# M481_v1 register map
File version: 1.0
Registers are 32-bit, read-write, reset 0x0 unless marked. A register's access mark holds for its fields unless they carry their own. Offsets are from the block's base; [hi:lo] are bit positions; {n}, {i} and the like mark numbered series; 'fields as' and 'values as' point back to an identical list.

## EADC0 — EADC Register Map
Base 0x40043000
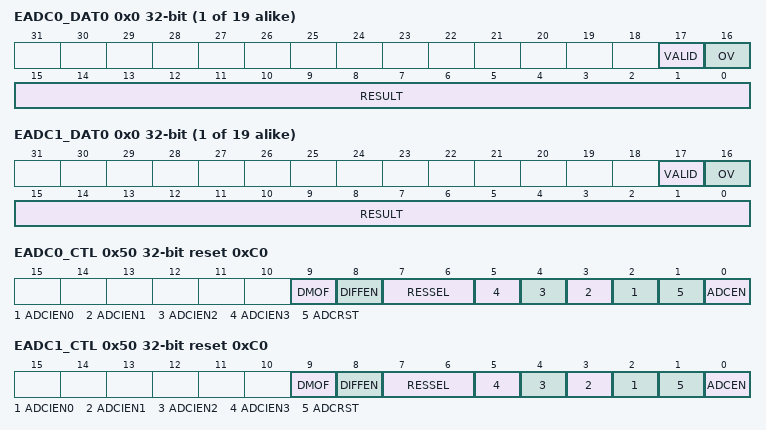
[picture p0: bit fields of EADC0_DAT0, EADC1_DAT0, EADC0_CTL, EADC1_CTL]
{0x0+4i} EADC0_DAT{i} ro (i=0..18) — EADC Data Register {i} for Sample Module {i}
  [17] VALID — Valid Flag. This bit is set to 1 when corresponding sample module channel analog input conversion is completed and cleared by hardware after EADC_DAT register is read.
    0=Data in RESULT[11:0] bits is not valid; 1=Data in RESULT[11:0] bits is valid
  [16] OV — Overrun Flag. If converted data in RESULT[11:0] has not been read before new conversion result is loaded to this register, OV is set to 1. Note: It is cleared by hardware after EADC_DAT register is read.
    0=Data in RESULT[11:0] is recent conversion result; 1=Data in RESULT[11:0] is overwrite
  [15:0] RESULT — EADC Conversion Result. This field contains 12 bits conversion result. When DMOF (EADC_CTL[9]) is set to 0, 12-bit EADC conversion result with unsigned format will be filled in RESULT[11:0] and zero will be filled in RESULT[15:12]. When DMOF (EADC_CTL[9]) set to 1, 12-bit EADC conversion result with 2'complement format will be filled in RESULT[11:0] and signed bits to will be filled in RESULT[15:12].
{0x0+4i} EADC1_DAT{i} ro (alternate view of EADC0_DAT{i}) (i=0..18) — EADC Data Register {i} for Sample Module {i}
  fields as EADC0_DAT0
0x4C EADC0_CURDAT ro — EADC PDMA Current Transfer Data Register
  [17:0] CURDAT — EADC PDMA Current Transfer Data (Read Only)
0x4C EADC1_CURDAT ro (alternate view of EADC0_CURDAT) — EADC PDMA Current Transfer Data Register
  [17:0] CURDAT — EADC PDMA Current Transfer Data (Read Only)
0x50 EADC0_CTL reset 0xC0 — EADC Control Register
  [9] DMOF — EADC Differential Input Mode Output Format
    0=EADC conversion result will be filled in RESULT (EADC_DATn[15:0], where n= 0 ~18) with unsigned format; 1=EADC conversion result will be filled in RESULT (EADC_DATn[15:0], where n= 0 ~18) with 2'complement format
  [8] DIFFEN — Differential Analog Input Mode Enable Bit
    0=Single-end analog input mode; 1=Differential analog input mode
  [7:6] RESSEL — Resolution Selection
    0=6-bit EADC result will be put at RESULT (EADC_DATn[5:0]); 1=8-bit EADC result will be put at RESULT (EADC_DATn[7:0]); 2=10-bit EADC result will be put at RESULT (EADC_DATn[9:0]); 3=12-bit EADC result will be put at RESULT (EADC_DATn[11:0])
  [n+2] ADCIEN{n} (n=0..3) — Specific Sample Module EADC ADINT{n} Interrupt Enable Bit. The EADC converter generates a conversion end ADIF{n} (EADC_STATUS2[{n}]) upon the end of specific sample module EADC conversion. If EADCIEN{n} bit is set then conversion end interrupt request ADINT{n} is generated.
    0=Specific sample module EADC ADINT{n} interrupt function Disabled; 1=Specific sample module EADC ADINT{n} interrupt function Enabled
  [1] ADCRST — EADC Converter Control Circuits Reset. Note: EADCRST bit remains 1 during EADC reset, when EADC reset end, the EADCRST bit is automatically cleared to 0.
    0=No effect; 1=Cause EADC control circuits reset to initial state, but not change the EADC registers value
  [0] ADCEN — EADC Converter Enable Bit. Note: Before starting EADC conversion function, this bit should be set to 1. Clear it to 0 to disable EADC converter analog circuit power consumption.
    0=Disabled EADC; 1=Enabled EADC
0x50 EADC1_CTL reset 0xC0 (alternate view of EADC0_CTL) — EADC Control Register
  fields as EADC0_CTL
0x54 EADC0_SWTRG wo — EADC Sample Module Software Start Register
  [18:0] SWTRG — EADC Sample Module 0~18 Software Force to Start EADC Conversion. Note: After writing this register to start EADC conversion, the EADC_PENDSTS register will show which sample module will conversion. If user want to disable the conversion of the sample module, user can write EADC_PENDSTS register to clear it.
    0=No effect; 1=Cause an EADC conversion when the priority is given to sample module
0x54 EADC1_SWTRG wo (alternate view of EADC0_SWTRG) — EADC Sample Module Software Start Register
  fields as EADC0_SWTRG
0x58 EADC0_PENDSTS — EADC Start of Conversion Pending Flag Register
  [18:0] STPF — EADC Sample Module 0~18 Start of Conversion Pending Flag. Read Operation:
    0=There is no pending conversion for sample module; 1=Sample module EADC start of conversion is pending. Cear pending flag cancel the conversion for sample module
0x58 EADC1_PENDSTS (alternate view of EADC0_PENDSTS) — EADC Start of Conversion Pending Flag Register
  fields as EADC0_PENDSTS
0x5C EADC0_OVSTS — EADC Sample Module Start of Conversion Overrun Flag Register
  [18:0] SPOVF — EADC SAMPLE0~18 Overrun Flag. Note: This bit is cleared by writing 1 to it.
    0=No sample module event overrun; 1=Indicates a new sample module event is generated while an old one event is pending
0x5C EADC1_OVSTS (alternate view of EADC0_OVSTS) — EADC Sample Module Start of Conversion Overrun Flag Register
  fields as EADC0_OVSTS
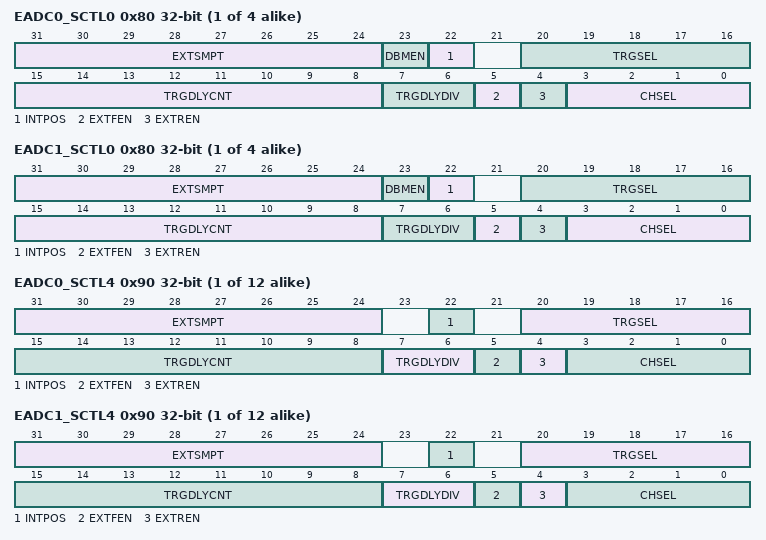
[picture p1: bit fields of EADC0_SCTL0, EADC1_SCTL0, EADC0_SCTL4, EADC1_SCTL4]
{0x80+4i} EADC0_SCTL{i} (i=0..3) — EADC Sample Module {i} Control Register
  [31:24] EXTSMPT — EADC Sampling Time Extend. When EADC converting at high conversion rate, the sampling time of analog input voltage may not enough if input channel loading is heavy, user can extend EADC sampling time after trigger source is coming to get enough sampling time. The range of start delay time is from 0~255 EADC clock.
  [23] DBMEN — Double Buffer Mode Enable Bit
    0=Sample has one sample result register (default); 1=Sample has two sample result registers
  [22] INTPOS — Interrupt Flag Position Select
    0=Set ADIFn (EADC_STATUS2[n], n=0~3) at EADC end of conversion; 1=Set ADIFn (EADC_STATUS2[n], n=0~3) at EADC start of conversion
  [20:16] TRGSEL — EADC Sample Module Start of Conversion Trigger Source Selection
  [15:8] TRGDLYCNT — EADC Sample Module Start of Conversion Trigger Delay Time
  [7:6] TRGDLYDIV — EADC Sample Module Start of Conversion Trigger Delay Clock Divider Selection. Trigger delay clock frequency:
    0=EADC_CLK/1; 1=EADC_CLK/2; 2=EADC_CLK/4; 3=EADC_CLK/16
  [5] EXTFEN — EADC External Trigger Falling Edge Enable Bit
    0=Falling edge Disabled when EADC selects EADC0_ST as trigger source; 1=Falling edge Enabled when EADC selects EADC0_ST as trigger source
  [4] EXTREN — EADC External Trigger Rising Edge Enable Bit
    0=Rising edge Disabled when EADC selects EADC0_ST as trigger source; 1=Rising edge Enabled when EADC selects EADC0_ST as trigger source
  [3:0] CHSEL — EADC Sample Module Channel Selection
{0x80+4i} EADC1_SCTL{i} (alternate view of EADC0_SCTL{i}) (i=0..3) — EADC Sample Module {i} Control Register
  fields as EADC0_SCTL0
{0x80+4i} EADC0_SCTL{i} (i=4..15) — EADC Sample Module {i} Control Register
  [31:24] EXTSMPT — EADC Sampling Time Extend. When EADC converting at high conversion rate, the sampling time of analog input voltage may not enough if input channel loading is heavy, SW can extend EADC sampling time after trigger source is coming to get enough sampling time. The range of start delay time is from 0~255 EADC clock.
  [22] INTPOS — Interrupt Flag Position Select
    values as EADC0_SCTL0.INTPOS
  [20:16] TRGSEL — EADC Sample Module Start of Conversion Trigger Source Selection
  [15:8] TRGDLYCNT — EADC Sample Module Start of Conversion Trigger Delay Time
  [7:6] TRGDLYDIV — EADC Sample Module Start of Conversion Trigger Delay Clock Divider Selection. Trigger delay clock frequency:
    0=EADC_CLK/1; 1=EADC_CLK/2; 2=EADC_CLK/4; 3=EADC_CLK/16
  [5] EXTFEN — EADC External Trigger Falling Edge Enable Bit
    values as EADC0_SCTL0.EXTFEN
  [4] EXTREN — EADC External Trigger Rising Edge Enable Bit
    values as EADC0_SCTL0.EXTREN
  [3:0] CHSEL — EADC Sample Module Channel Selection
{0x80+4i} EADC1_SCTL{i} (alternate view of EADC0_SCTL{i}) (i=4..15) — EADC Sample Module {i} Control Register
  fields as EADC0_SCTL4
{0x80+4i} EADC0_SCTL{i} (i=16..18) — EADC Sample Module {i} Control Register
  [31:24] EXTSMPT — EADC Sampling Time Extend. When EADC converting at high conversion rate, the sampling time of analog input voltage may not enough if input channel loading is heavy, SW can extend EADC sampling time after trigger source is coming to get enough sampling time. The range of start delay time is from 0~255 EADC clock.
{0x80+4i} EADC1_SCTL{i} (alternate view of EADC0_SCTL{i}) (i=16..18) — EADC Sample Module {i} Control Register
  fields as EADC0_SCTL16
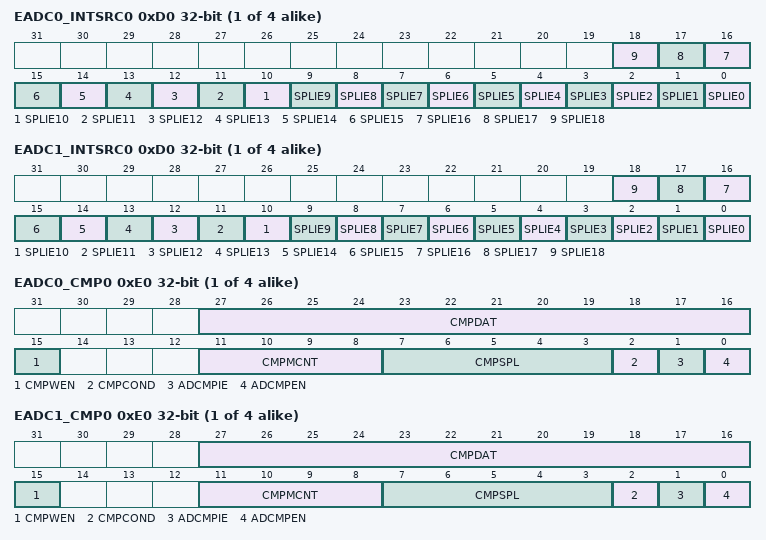
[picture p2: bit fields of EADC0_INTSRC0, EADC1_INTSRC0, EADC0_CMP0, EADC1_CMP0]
{0xD0+4i} EADC0_INTSRC{i} (i=0..3) — EADC Interrupt {i} Source Enable Control Register.
  [n] SPLIE{n} (n=0..18) — Sample Module {n} Interrupt Enable Bit
    0=Sample Module {n} interrupt Disabled; 1=Sample Module {n} interrupt Enabled
{0xD0+4i} EADC1_INTSRC{i} (alternate view of EADC0_INTSRC{i}) (i=0..3) — EADC Interrupt {i} Source Enable Control Register.
  fields as EADC0_INTSRC0
{0xE0+4i} EADC0_CMP{i} (i=0..3) — EADC Result Compare Register {i}
  [27:16] CMPDAT — Comparison Data. The 12 bits data is used to compare with conversion result of specified sample module. User can use it to monitor the external analog input pin voltage transition without imposing a load on software.
  [15] CMPWEN — Compare Window Mode Enable Bit. Note: This bit is only present in EADC_CMP0 and EADC_CMP2 register.
    0=EADCMPF0 (EADC_STATUS2[4]) will be set when EADC_CMP0 compared condition matched. EADCMPF2 (EADC_STATUS2[6]) will be set when EADC_CMP2 compared condition matched; 1=EADCMPF0 (EADC_STATUS2[4]) will be set when both EADC_CMP0 and EADC_CMP1 compared condition matched. EADCMPF2 (EADC_STATUS2[6]) will be set when both EADC_CMP2 and EADC_CMP3 compared condition matched
  [11:8] CMPMCNT — Compare Match Count
  [7:3] CMPSPL — Compare Sample Module Selection
    {v}=Sample Module {v} conversion result EADC_DAT{v} is selected to be compared (v=0..18)
  [2] CMPCOND — Compare Condition
    0=Set the compare condition as that when a 12-bit EADC conversion result is less than the 12-bit CMPDAT (EADC_CMPn [27:16]), the internal match counter will increase one; 1=Set the compare condition as that when a 12-bit EADC conversion result is greater or equal to the 12-bit CMPDAT (EADC_CMPn [27:16]), the internal match counter will increase one
  [1] ADCMPIE — EADC Result Compare Interrupt Enable Bit
    0=Compare function interrupt Disabled; 1=Compare function interrupt Enabled
  [0] ADCMPEN — EADC Result Compare Enable Bit
    0=Compare Disabled; 1=Compare Enabled
{0xE0+4i} EADC1_CMP{i} (alternate view of EADC0_CMP{i}) (i=0..3) — EADC Result Compare Register {i}
  fields as EADC0_CMP0
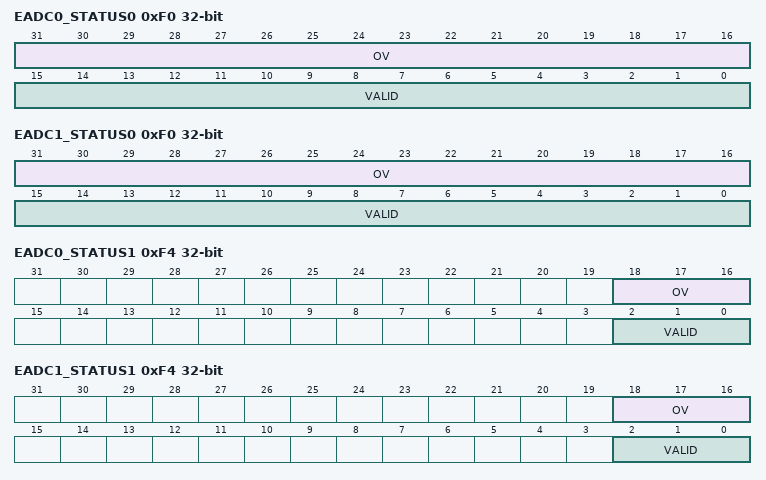
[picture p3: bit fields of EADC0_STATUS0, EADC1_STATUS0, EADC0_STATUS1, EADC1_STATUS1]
0xF0 EADC0_STATUS0 ro — EADC Status Register 0
  [31:16] OV — EADC_DAT0~15 Overrun Flag
  [15:0] VALID — EADC_DAT0~15 Data Valid Flag
0xF0 EADC1_STATUS0 ro (alternate view of EADC0_STATUS0) — EADC Status Register 0
  fields as EADC0_STATUS0
0xF4 EADC0_STATUS1 ro — EADC Status Register 1
  [18:16] OV — EADC_DAT16~18 Overrun Flag
  [2:0] VALID — EADC_DAT16~18 Data Valid Flag
0xF4 EADC1_STATUS1 ro (alternate view of EADC0_STATUS1) — EADC Status Register 1
  fields as EADC0_STATUS1
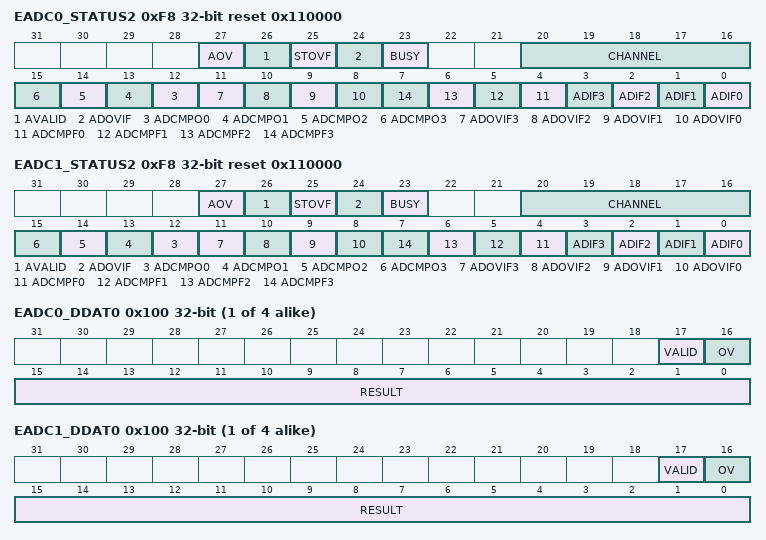
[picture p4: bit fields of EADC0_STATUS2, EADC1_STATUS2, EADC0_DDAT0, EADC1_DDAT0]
0xF8 EADC0_STATUS2 reset 0x110000 — EADC Status Register 2
  [27] AOV ro — for All Sample Module EADC Result Data Register Overrun Flags Check (Read Only). Note: This bit will keep 1 when any OVn Flag is equal to 1.
    0=None of sample module data register overrun flag OVn (EADC_DATn[16]) is set to 1; 1=Any one of sample module data register overrun flag OVn (EADC_DATn[16]) is set to 1
  [26] AVALID ro — for All Sample Module EADC Result Data Register EADC_DAT Data Valid Flag Check (Read Only). Note: This bit will keep 1 when any VALIDn Flag is equal to 1.
    0=None of sample module data register valid flag VALIDn (EADC_DATn[17]) is set to 1; 1=Any one of sample module data register valid flag VALIDn (EADC_DATn[17]) is set to 1
  [25] STOVF ro — for All EADC Sample Module Start of Conversion Overrun Flags Check (Read Only). Note: This bit will keep 1 when any SPOVFn Flag is equal to 1.
    0=None of sample module event overrun flag SPOVFn (EADC_OVSTS[n]) is set to 1; 1=Any one of sample module event overrun flag SPOVFn (EADC_OVSTS[n]) is set to 1
  [24] ADOVIF ro — All EADC Interrupt Flag Overrun Bits Check (Read Only). Note: This bit will keep 1 when any ADOVIFn Flag is equal to 1.
    0=None of ADINT interrupt flag ADOVIFn (EADC_STATUS2[11:8]) is overwritten to 1; 1=Any one of ADINT interrupt flag ADOVIFn (EADC_STATUS2[11:8]) is overwritten to 1
  [23] BUSY ro — Busy/Idle (Read Only)
    0=EADC is in idle state; 1=EADC is busy at conversion
  [20:16] CHANNEL ro — Current Conversion Channel (Read Only)
  [n+12] ADCMPO{n} ro (n=0..3) — EADC Compare {n} Output Status (Read Only). The 12 bits compare{n} data CMPDAT{n} (EADC_CMP{n}[27:16]) is used to compare with conversion result of specified sample module. User can use it to monitor the external analog input pin voltage status.
    0=Conversion result in EADC_DAT less than CMPDAT{n} setting; 1=Conversion result in EADC_DAT great than or equal CMPDAT{n} setting
  [11] ADOVIF3 — EADC ADINT3 Interrupt Flag Overrun. Note: This bit is cleared by writing 1 to it.
    0=ADINT3 interrupt flag is not overwritten to 1; 1=ADINT3 interrupt flag is overwritten to 1
  [10] ADOVIF2 — EADC ADINT2 Interrupt Flag Overrun. Note: This bit is cleared by writing 1 to it.
    0=ADINT2 interrupt flag is not overwritten to 1; 1=ADINT2 interrupt flag is s overwritten to 1
  [9] ADOVIF1 — EADC ADINT1 Interrupt Flag Overrun. Note: This bit is cleared by writing 1 to it.
    0=ADINT1 interrupt flag is not overwritten to 1; 1=ADINT1 interrupt flag is overwritten to 1
  [8] ADOVIF0 — EADC ADINT0 Interrupt Flag Overrun. Note: This bit is cleared by writing 1 to it.
    0=ADINT0 interrupt flag is not overwritten to 1; 1=ADINT0 interrupt flag is overwritten to 1
  [n+4] ADCMPF{n} (n=0..3) — EADC Compare {n} Flag. When the specific sample module EADC conversion result meets setting condition in EADC_CMP{n} then this bit is set to 1. Note: This bit is cleared by writing 1 to it.
    0=Conversion result in EADC_DAT does not meet EADC_CMP{n} register setting; 1=Conversion result in EADC_DAT meets EADC_CMP{n} register setting
  [n] ADIF{n} (n=0..3) — EADC ADINT{n} Interrupt Flag. Note 1: This bit is cleared by writing 1 to it. Note 2:This bit indicates whether an EADC conversion of specific sample module has been completed
    0=No ADINT{n} interrupt pulse received; 1=ADINT{n} interrupt pulse has been received
0xF8 EADC1_STATUS2 reset 0x110000 (alternate view of EADC0_STATUS2) — EADC Status Register 2
  fields as EADC0_STATUS2
0xFC EADC0_STATUS3 ro reset 0x1F — EADC Status Register 3
  [4:0] CURSPL — EADC Current Sample Module (Read Only). This register shows the current EADC is controlled by which sample module control logic modules. If the EADC is Idle, the bit filed will set to 0x1F.
0xFC EADC1_STATUS3 ro reset 0x1F (alternate view of EADC0_STATUS3) — EADC Status Register 3
  fields as EADC0_STATUS3
{0x100+4i} EADC0_DDAT{i} ro (i=0..3) — EADC Double Data Register {i} for Sample Module {i}
  [17] VALID — Valid Flag
    0=Double data in RESULT (EADC_DDATn[15:0]) is not valid; 1=Double data in RESULT (EADC_DDATn[15:0]) is valid
  [16] OV — Overrun Flag. If converted data in RESULT[15:0] has not been read before new conversion result is loaded to this register, OV is set to 1. It is cleared by hardware after EADC_DDAT register is read.
    0=Data in RESULT (EADC_DATn[15:0], n=0~3) is recent conversion result; 1=Data in RESULT (EADC_DATn[15:0], n=0~3) is overwrite
  [15:0] RESULT — EADC Conversion Results. This field contains 12 bits conversion results. When the DMOF (EADC_CTL[9]) is set to 0, 12-bit EADC conversion result with unsigned format will be filled in RESULT [11:0] and zero will be filled in RESULT [15:12]. When DMOF (EADC_CTL[9]) is set to 1, 12-bit EADC conversion result with 2'complement format will be filled in RESULT [11:0] and signed bits to will be filled in RESULT [15:12].
{0x100+4i} EADC1_DDAT{i} ro (alternate view of EADC0_DDAT{i}) (i=0..3) — EADC Double Data Register {i} for Sample Module {i}
  fields as EADC0_DDAT0
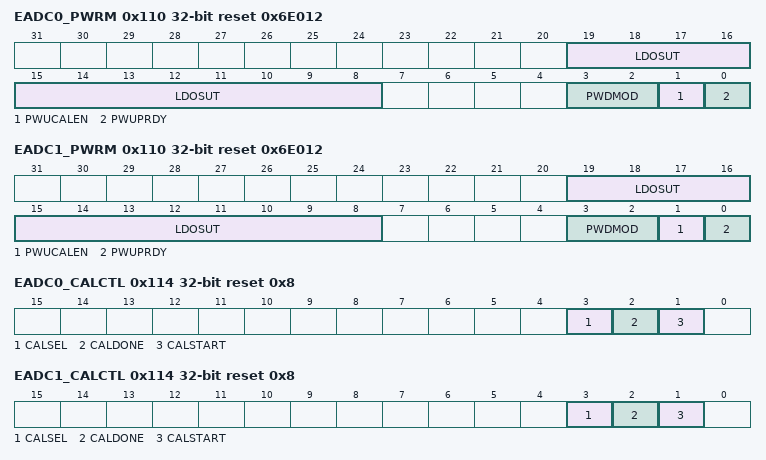
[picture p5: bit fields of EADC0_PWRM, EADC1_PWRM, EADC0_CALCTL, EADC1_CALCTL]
0x110 EADC0_PWRM reset 0x6E012 — EADC Power Management Register
  [19:8] LDOSUT — EADC Internal LDO Start-up Time
  [3:2] PWDMOD — EADC Power-down Mode. Set this bit field to select EADC Power-down mode when system power-down. Note: Different PWDMOD has different power down/up sequence, in order to avoid EADC powering up with wrong sequence; user must keep PWDMOD consistent each time in power down and start up.
    0=EADC Deep Power-down mode; 1=EADC Power down; 2=EADC Standby mode; 3=EADC Deep Power-down mode
  [1] PWUCALEN — Power Up Calibration Function Enable Bit. Note: This bit work together with CALSEL (EADC_CALCTL [3]), see the following {PWUCALEN, CALSEL } Description: PWUCALEN is 0 and CALSEL is 0: No need to calibrate. PWUCALEN is 0 and CALSEL is 1: No need to calibrate. PWUCALEN is 1 and CALSEL is 0: Load calibration word when power up. PWUCALEN is 1 and CALSEL is 1: Calibrate when power up.
    0=Calibration function Disabled at power up; 1=Calibration function Enabled at power up
  [0] PWUPRDY ro — EADC Power-up Sequence Completed and Ready for Conversion (Read Only)
    0=EADC is not ready for conversion may be in power down state or in the progress of start up; 1=EADC is ready for conversion
0x110 EADC1_PWRM reset 0x6E012 (alternate view of EADC0_PWRM) — EADC Power Management Register
  fields as EADC0_PWRM
0x114 EADC0_CALCTL reset 0x8 — EADC Calibration Control Register
  [3] CALSEL — Select Calibration Functional Block
    0=Load calibration word when calibration functional block is active; 1=Execute calibration when calibration functional block is active
  [2] CALDONE ro — Calibration Functional Block Complete (Read Only)
    0=During a calibration; 1=Calibration is completed
  [1] CALSTART — Calibration Functional Block Start. Note 1: This bit is set by SW and clear by HW after re-calibration finish. Note 2: Before set CALSTART (EADC_CALCTL[1]) as 1 to start calibration again, EADCDIV (CKL_CLKDIV0[23:16]) must be 0.
    0=Stop calibration functional block; 1=Start calibration functional block
0x114 EADC1_CALCTL reset 0x8 (alternate view of EADC0_CALCTL) — EADC Calibration Control Register
  fields as EADC0_CALCTL
0x118 EADC0_CALDWRD (reset mask 0xFFFFFF00) — EADC Calibration Load Word Register
  [6:0] CALWORD — Calibration Word Bits. Write to this register with the previous calibration word before load calibration action. Read this register after calibration done. Note: The calibration block contains two parts 'CALIBRATION' and 'LOAD CALIBRATION'; if the calibration block configure as 'CALIBRATION'; then this register represent the result of calibration when calibration is completed; if configure as 'LOAD CALIBRATION' ; configure this register before loading calibration action, after loading calibration complete, the laoded calibration word will apply to the EADC; while in loading calibration function the loaded value will not be equal to the original CALWORD until calibration is done.
0x118 EADC1_CALDWRD (reset mask 0xFFFFFF00) (alternate view of EADC0_CALDWRD) — EADC Calibration Load Word Register
  fields as EADC0_CALDWRD
0x130 EADC0_PDMACTL — EADC PDMA Control Register
  [18:0] PDMATEN — PDMA Transfer Enable Bit. When EADC conversion is completed, the converted data is loaded into EADC_DATn (n: 0 ~ 18) register, user can enable this bit to generate a PDMA data transfer request.
    0=PDMA data transfer Disabled; 1=PDMA data transfer Enabled
0x130 EADC1_PDMACTL (alternate view of EADC0_PDMACTL) — EADC PDMA Control Register
  fields as EADC0_PDMACTL
